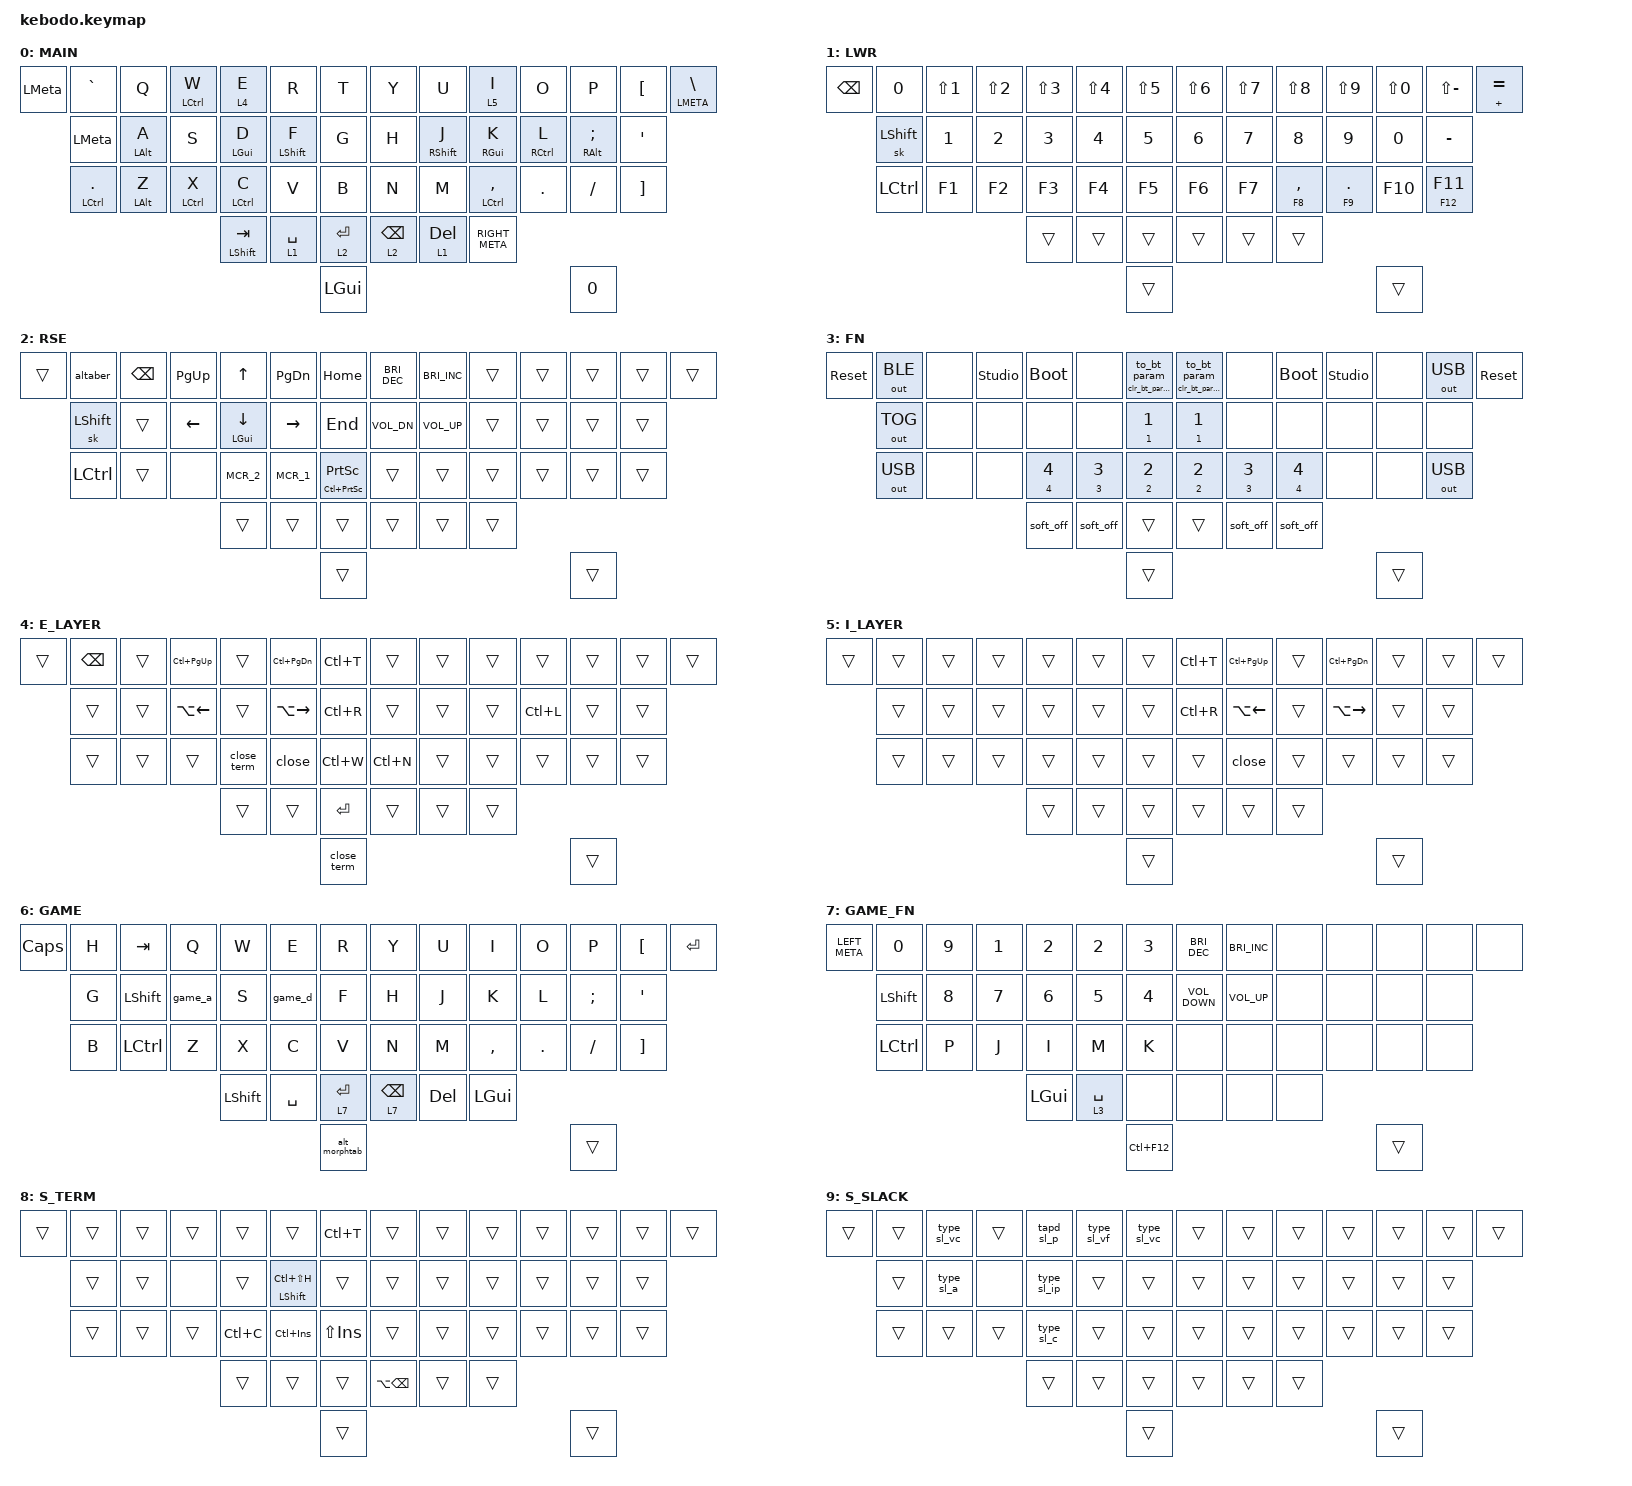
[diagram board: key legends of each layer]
/*
 * Copyright (c) 2020 The ZMK Contributors
 *
 * SPDX-License-Identifier: MIT
 */

#include <behaviors.dtsi>
#include <dt-bindings/zmk/bt.h>
#include <dt-bindings/zmk/keys.h>
#include <dt-bindings/zmk/outputs.h>

#define DEF 0
#define LWR 1
#define RSE 2
#define FN  3

&lt { require-prior-idle-ms = <140>; };

&mt {
    quick-tap-ms = <200>;
    flavor = "balanced";
};

/ {
    combos {
        compatible = "zmk,combos";

        game_mod_on {
            bindings = <&to 6>;
            key-positions = <6 5 39>;
            layers = <0 6>;
        };

        game_mod_off {
            bindings = <&to 0>;
            key-positions = <6 5 40>;
        };

        Esc {
            bindings = <&kp ESCAPE>;
            key-positions = <1 2>;
            layers = <0 1 6 7 3>;
        };

        slash {
            bindings = <&kp RA(SLASH)>;
            key-positions = <6 19>;
        };

        CapsWord {
            bindings = <&caps_word>;
            key-positions = <18 21>;
        };

        Backspace {
            bindings = <&kp INS>;
            key-positions = <11 12>;
        };

        at {
            bindings = <&kp AT_SIGN>;
            key-positions = <2 3>;
        };

        minus {
            bindings = <&tp_minus_underscore>;
            key-positions = <8 9>;
        };

        LPare {
            bindings = <&kp LEFT_PARENTHESIS>;
            key-positions = <21 22>;
        };

        RPare {
            bindings = <&kp RIGHT_PARENTHESIS>;
            key-positions = <22 23>;
        };

        Plus {
            bindings = <&tp_plus_equal>;
            key-positions = <9 10>;
        };

        Comma {
            bindings = <&kp RA(COMMA)>;
            key-positions = <33 32>;
        };

        Question {
            bindings = <&kp RA(QUESTION)>;
            key-positions = <7 8>;
        };

        Dot {
            bindings = <&kp RA(PERIOD)>;
            key-positions = <20 21>;
        };

        LBrac {
            bindings = <&mt LEFT_BRACE LEFT_BRACKET>;
            key-positions = <33 34>;
        };

        RBrac {
            bindings = <&mt RIGHT_BRACE RIGHT_BRACKET>;
            key-positions = <34 35>;
        };

        Quotes {
            bindings = <&kp RA(SQT)>;
            key-positions = <24 23>;
        };

        ret {
            bindings = <&kp RET>;
            key-positions = <22 23 21>;
        };

        bspace2 {
            bindings = <&morph_del>;
            key-positions = <17 16>;
            layers = <0 1 2>;
        };

        Question2 {
            bindings = <&kp RA(QUESTION)>;
            key-positions = <11 10>;
            layers = <0 1 2 3 4>;
        };

        toSwap {
            bindings = <&kp LC(LA(LS(C)))>;
            key-positions = <28 29>;
            layers = <0>;
        };

        at2 {
            bindings = <&kp AT_SIGN>;
            key-positions = <3 4>;
        };

        esc2 {
            bindings = <&kp ESCAPE>;
            key-positions = <2 3>;
            layers = <6 7>;
        };
    };

    behaviors {
        altaber: altaber {
            compatible = "zmk,behavior-tri-state";
            label = "ALT Win Switcher";
            #binding-cells = <0>;
            bindings = <&kt LGUI>, <&kp TAB>, <&kt LGUI>;
        };

        bt_select: bt_select {
            compatible = "zmk,behavior-hold-tap";
            label = "BT_SELECT";
            bindings = <&clr_bt_param>, <&to_bt_param>;

            #binding-cells = <2>;
            tapping-term-ms = <3000>;
        };

        LMeta: LMeta {
            compatible = "zmk,behavior-mod-morph";
            label = "LMETA";
            bindings = <&mt LEFT_META LG(SPACE)>, <&altaber>;

            #binding-cells = <0>;
            mods = <(MOD_LSFT)>;
        };

        alt_morphtab: alt_morphtab {
            compatible = "zmk,behavior-mod-morph";
            label = "ALT_MORPHTAB";
            bindings = <&kp LEFT_ALT>, <&kp TAB>;

            #binding-cells = <0>;
            mods = <(MOD_LALT|MOD_RALT|MOD_RGUI|MOD_LGUI)>;
            keep-mods = <(MOD_LALT|MOD_RALT|MOD_LGUI|MOD_RGUI)>;
        };

        morph_del: morph_del {
            compatible = "zmk,behavior-mod-morph";
            label = "MORPH_DEL";
            bindings = <&kp BACKSPACE>, <&kp DEL>;

            #binding-cells = <0>;
            mods = <(MOD_LSFT)>;
        };

        HR: HR {
            compatible = "zmk,behavior-hold-tap";
            label = "HR";
            bindings = <&kp>, <&kp>;

            #binding-cells = <2>;
            tapping-term-ms = <180>;
            flavor = "balanced";
            require-prior-idle-ms = <140>;
            quick-tap-ms = <(-1)>;
        };

        HR_S: HR_S {
            compatible = "zmk,behavior-hold-tap";
            label = "HR_S";
            bindings = <&kp>, <&kp>;

            #binding-cells = <2>;
            tapping-term-ms = <180>;
            flavor = "balanced";
            require-prior-idle-ms = <140>;
            hold-while-undecided;
            quick-tap-ms = <(-1)>;
        };

        HR_C: HR_C {
            compatible = "zmk,behavior-hold-tap";
            label = "HR_C";
            bindings = <&kp>, <&kp>;

            #binding-cells = <2>;
            tapping-term-ms = <180>;
            flavor = "tap-preferred";
            require-prior-idle-ms = <140>;
            hold-while-undecided;
            quick-tap-ms = <(-1)>;
        };

        tp_plus_equal: tp_plus_equal {
            compatible = "zmk,behavior-mod-morph";
            label = "TP_PLUS_EQUAL";
            bindings = <&kp KP_EQUAL>, <&kp PLUS>;

            #binding-cells = <0>;
            mods = <(MOD_LSFT|MOD_RSFT)>;
        };

        tp_minus_underscore: tp_minus_underscore {
            compatible = "zmk,behavior-mod-morph";
            label = "TP_MINUS_UNDERSCORE";
            bindings = <&kp MINUS>, <&kp UNDERSCORE>;

            #binding-cells = <0>;
            mods = <(MOD_LSFT|MOD_RSFT)>;
        };

        HR_A: HR_A {
            compatible = "zmk,behavior-hold-tap";
            label = "HR_A";
            bindings = <&kp>, <&kp>;

            #binding-cells = <2>;
            tapping-term-ms = <180>;
            flavor = "tap-preferred";
            require-prior-idle-ms = <140>;
            quick-tap-ms = <(-1)>;
        };

        thumb_lt: thumb_lt {
            compatible = "zmk,behavior-hold-tap";
            label = "THUMB_LT";
            bindings = <&mo>, <&kp>;

            #binding-cells = <2>;
            tapping-term-ms = <180>;
            quick-tap-ms = <220>;
            require-prior-idle-ms = <140>;
            flavor = "tap-preferred";
        };

        tapd_sl_p: tapd_sl_p {
            compatible = "zmk,behavior-tap-dance";
            label = "TAPD_SL_P";
            #binding-cells = <0>;
            tapping-term-ms = <2000>;
            bindings = <&type_sl_p>, <&type_sl_priority>;
        };
    };

    macros {
        to_bt_param: to_bt_param {
            compatible = "zmk,behavior-macro-one-param";
            #binding-cells = <1>;
            bindings =
                <&macro_press>,
                <&out OUT_BLE &macro_param_1to2>,
                <&macro_press>,
                <&bt BT_SEL MACRO_PLACEHOLDER>;

            label = "TO_BT_PARAM";
        };

        clr_bt_param: clr_bt_param {
            compatible = "zmk,behavior-macro-one-param";
            #binding-cells = <1>;
            bindings =
                <&macro_press>,
                <&out OUT_BLE &macro_param_1to2>,
                <&macro_press>,
                <&bt BT_SEL MACRO_PLACEHOLDER>,
                <&macro_press>,
                <&bt BT_CLR>;

            label = "CLR_BT_PARAM";
        };

        close_term: close_term {
            compatible = "zmk,behavior-macro";
            #binding-cells = <0>;
            bindings = <&kp Q &kp LC(C) &kp LC(D)>;
            label = "CLOSE_TERM";
        };

        game_d: game_d {
            compatible = "zmk,behavior-macro";
            #binding-cells = <0>;
            bindings =
                <&macro_release>,
                <&kp A>,
                <&macro_press>,
                <&kp D>,
                <&macro_pause_for_release>,
                <&macro_release>,
                <&kp D>;

            label = "GAME_D";
        };

        game_a: game_a {
            compatible = "zmk,behavior-macro";
            #binding-cells = <0>;
            bindings =
                <&macro_release>,
                <&kp D>,
                <&macro_press>,
                <&kp A>,
                <&macro_pause_for_release>,
                <&macro_release>,
                <&kp A>;

            label = "GAME_A";
        };

        MCR_1: MCR_1 {
            compatible = "zmk,behavior-macro";
            #binding-cells = <0>;
            bindings = <&kp LS(LC(F1)) &kp LS(C) &kp O &kp D &kp E &kp N1 &kp LS(W) &kp E &kp W &kp E>;
            label = "MCR_1";
        };

        MCR_2: MCR_2 {
            compatible = "zmk,behavior-macro";
            #binding-cells = <0>;
            bindings = <&kp LC(LS(F1)) &kp D &kp I &kp N9 &kp B &kp S &kp LS(D) &kp U &kp N>;
            label = "MCR_2";
        };

        close: close {
            compatible = "zmk,behavior-macro";
            #binding-cells = <0>;
            bindings = <&kp LC(W) &kp F13>;
            label = "CLOSE";
        };

        type_sl_a: type_sl_a {
            compatible = "zmk,behavior-macro";
            #binding-cells = <0>;
            bindings = <&kp LS(LC(F1)) &kp PERIOD &kp DOT &kp A>;
            label = "TYPE_SL_A";
        };

        type_sl_ip: type_sl_ip {
            compatible = "zmk,behavior-macro";
            #binding-cells = <0>;
            bindings = <&kp LS(LC(F1)) &kp DOT &kp DOT &kp I &kp P &kp SPACE>;
            label = "TYPE_SL_IP";
        };

        type_sl_vf: type_sl_vf {
            compatible = "zmk,behavior-macro";
            #binding-cells = <0>;
            bindings = <&kp LS(LC(F1)) &kp DOT &kp DOT &kp V &kp F &kp SPACE>;
            label = "TYPE_SL_VF";
        };

        type_sl_vc: type_sl_vc {
            compatible = "zmk,behavior-macro";
            #binding-cells = <0>;
            bindings = <&kp LS(LC(F1)) &kp DOT &kp DOT &kp V &kp C &kp SPACE &kp D &kp O &kp N &kp E>;
            label = "TYPE_SL_VC";
        };

        type_sl_c: type_sl_c {
            compatible = "zmk,behavior-macro";
            #binding-cells = <0>;
            bindings = <&kp RS(LS(F1)) &kp DOT &kp DOT &kp C &kp SPACE>;
            label = "TYPE_SL_C";
        };

        type_systemctl: type_systemctl {
            compatible = "zmk,behavior-macro";
            #binding-cells = <0>;
            bindings = <&kp LS(LC(F1)) &kp S &kp Y &kp S &kp T &kp E &kp M &kp C &kp T &kp L &kp SPACE>;
            label = "TYPE_SYSTEMCTL";
        };

        type_user: type_user {
            compatible = "zmk,behavior-macro";
            #binding-cells = <0>;
            bindings = <&kp RS(LS(F1)) &kp MINUS &kp MINUS &kp U &kp S &kp E &kp R &kp SPACE>;
            label = "TYPE_USER";
        };

        type_status: type_status {
            compatible = "zmk,behavior-macro";
            #binding-cells = <0>;
            bindings = <&kp RS(LS(F1)) &kp S &kp T &kp A &kp T &kp U &kp S &kp SPACE>;
            label = "TYPE_STATUS";
        };

        type_sl_p: type_sl_p {
            compatible = "zmk,behavior-macro";
            #binding-cells = <0>;
            bindings = <&kp RS(LS(F1)) &kp DOT &kp DOT &kp P>;
            label = "TYPE_SL_P";
        };

        type_sl_priority: type_sl_priority {
            compatible = "zmk,behavior-macro";
            #binding-cells = <0>;
            bindings = <&kp R &kp I &kp O &kp R &kp I &kp T &kp Y &kp SPACE &kp LS(P) &kp N1>;
            label = "TYPE_SL_PRIORITY";
        };
    };

    keymap {
        compatible = "zmk,keymap";

        main {
            /* 
         ╭───────────────────────────────────╮                ╭───────────────────────────────────╮        
  ╭──────╯  ~  |  Q  |  W󰘴 |  E  |  R  |  T  │                │  Y  |  U  |  I  |  O  |  P  |  [  ╰───────╮
  │          |  A󰘵 |  S  |  D󰘳 |  F󰘶 |  G  │                │  H  |  J󰘶 |  K󰘳 |  L󰘴 |  ;󰘵 |  '     󰘳 \  │
  ╰──────╮  󰘵  |  Z  |  X  |  C  |  V  |  B  ╰─────╮    ╭─────╯  N  |  M  |  ,  |  .  |  /  |  ]  ╭───────╯
         ╰─────────────────╮ GUI |  󰌒  | 󱁐  | 󰌑  │    │ 󰁮  | 󰹾  |    ╭───────────────────────╯
                           ╰───────────────────────╯    ╰─────────────────╯
*/

            bindings = <
&LMeta  &kp GRAVE      &kp Q             &HR_C LCTRL W  &lt 4 E             &kp R              &kp T              &kp Y                  &kp U               &lt 5 I            &kp O          &kp P                      &kp LBKT           &mt LMETA BACKSLASH
        &LMeta         &HR_A LEFT_ALT A  &kp S          &HR LGUI D          &HR_S LSHFT F      &kp G              &kp H                  &HR_S RSHFT J       &HR RGUI K         &HR_C RCTRL L  &HR_A RIGHT_ALT SEMICOLON  &kp SQT
        &mt LCTRL DOT  &HR_A LEFT_ALT Z  &HR_C LCTRL X  &HR_C LCTRL C       &kp V              &kp B              &kp N                  &kp M               &HR_C LCTRL COMMA  &kp DOT        &kp FSLH                   &kp RIGHT_BRACKET
                                                        &mt LEFT_SHIFT TAB  &thumb_lt 1 SPACE  &thumb_lt 2 RET    &thumb_lt 2 BACKSPACE  &thumb_lt 1 DELETE  &kp RIGHT_META
                                                                                               &kp LGUI                                                                                        &kp N0
            >;

            label = "MAIN";
        };

        lwr {
            /* 
         ╭───────────────────────────────────╮                ╭────────────────────────────────────╮        
  ╭──────╯  󰁮  |  1  |  2  |  3  |  4  |  5  │                │  6  |  7  |  8  |  9  |  0  |  -   ╰───────╮
  │  󰁮     CTR |  !  |  @  |  #  |  $  |  %  │                │  ^  |  &  |  *  |  (  |  )  |  _       +=  │
  ╰──────╮ ALT |  󱊫  |  󱊬  |  󱊭  |  󱊮  |  󱊯  ╰─────╮    ╭─────╯  󱊰  |  󱊱  |  󱊲  |  󱊳  |  󱊴  | 󱊵 󱊶  ╭───────╯
         ╰─────────────────╮     |     |  󱎘  |     │    │     |  󱎘  |     ╭────────────────────────╯
                           ╰───────────────────────╯    ╰─────────────────╯
*/

            bindings = <
&kp BACKSPACE  &kp N0     &kp LS(N1)  &kp LS(N2)  &kp LS(N3)  &kp LS(N4)  &kp LS(N5)    &kp LS(N6)  &kp LS(N7)  &kp LS(N8)    &kp LS(N9)  &kp LS(N0)  &kp LS(MINUS)  &mt PLUS EQUAL
               &sk LSHFT  &kp N1      &kp N2      &kp N3      &kp N4      &kp N5        &kp N6      &kp N7      &kp N8        &kp N9      &kp N0      &kp MINUS
               &kp LCTRL  &kp F1      &kp F2      &kp F3      &kp F4      &kp F5        &kp F6      &kp F7      &mt F8 COMMA  &mt F9 DOT  &kp F10     &mt F12 F11
                                                  &trans      &trans      &trans        &trans      &trans      &trans
                                                                          &trans                                                          &trans
            >;

            label = "LWR";
        };

        rse {
            /* 
         ╭───────────────────────────────────╮                ╭───────────────────────────────────╮        
  ╭──────╯    |  󰁮  | PG |    | PG |  󰈙 │                │  󰃞  |  󰃠  |     |     |     |     ╰───────╮
  │         󰘶  |     |    |    |    |  󰈙 │                │    |    |     |     |     |             │
  ╰──────╮  󰘴  |     |     | mcr | mcr |  󰹑  ╰─────╮    ╭─────╯     |     |     |     |     |     ╭───────╯
         ╰─────────────────╮     |     |     |  󱎘  │    │  󱎘  |     |     ╭───────────────────────╯
                           ╰───────────────────────╯    ╰─────────────────╯
*/

            bindings = <
&trans  &altaber    &kp BACKSPACE  &kp PG_UP  &kp UP_ARROW             &kp PG_DN  &kp HOME                           &kp C_BRIGHTNESS_DEC  &kp C_BRIGHTNESS_INC  &trans  &trans  &trans  &trans  &trans
        &sk LSHIFT  &trans         &kp LEFT   &mt LEFT_GUI DOWN_ARROW  &kp RIGHT  &kp END                            &kp C_VOL_DN          &kp C_VOL_UP          &trans  &trans  &trans  &trans
        &kp LCTRL   &trans         &none      &MCR_2                   &MCR_1     &mt LC(PRINTSCREEN) PRINTSCREEN    &trans                &trans                &trans  &trans  &trans  &trans
                                              &trans                   &trans     &trans                             &trans                &trans                &trans
                                                                                  &trans                                                                                         &trans
            >;

            label = "RSE";
        };

        fn {
            /* 
         ╭───────────────────────────────────╮                ╭───────────────────────────────────╮        
  ╭──────╯  󰕓  |     |     |    |     |  0 │                │  0 |     |    |     |     |  󰕓  ╰───────╮
  │  󰑓     󰕓  |     |     |     |     |  1 │                │  1 |     |     |     |     |  󰕓     󰑓   │
  ╰──────╮    |     |     |  4 |  3 |  2 ╰─────╮    ╭─────╯  2 |  3 |  4 |     |     |    ╭───────╯
         ╰─────────────────╮    |    |  󱎘  |  󱎘  │    │  󱎘  |  󱎘  |    ╭───────────────────────╯
                           ╰───────────────────────╯    ╰─────────────────╯
*/

            bindings = <
&sys_reset  &out OUT_BLE  &none  &studio_unlock  &bootloader     &none           &bt_select 0 0    &bt_select 0 0  &none           &bootloader     &studio_unlock  &none   &out OUT_USB  &sys_reset
            &out OUT_TOG  &none  &none           &none           &none           &bt_select 1 1    &bt_select 1 1  &none           &none           &none           &none   &none
            &out OUT_USB  &none  &none           &bt_select 4 4  &bt_select 3 3  &bt_select 2 2    &bt_select 2 2  &bt_select 3 3  &bt_select 4 4  &none           &none   &out OUT_USB
                                                 &soft_off       &soft_off       &trans            &trans          &soft_off       &soft_off
                                                                                 &trans                                                                            &trans
            >;

            label = "FN";
        };

        e_layer {
            bindings = <
&trans  &kp BACKSPACE  &trans  &kp LC(PG_UP)       &trans       &kp LC(PG_DN)  &kp LC(T)      &trans     &trans  &trans  &trans     &trans  &trans  &trans
        &trans         &trans  &kp LA(LEFT_ARROW)  &trans       &kp LA(RIGHT)  &kp LC(R)      &trans     &trans  &trans  &kp LC(L)  &trans  &trans
        &trans         &trans  &trans              &close_term  &close         &kp LC(W)      &kp LC(N)  &trans  &trans  &trans     &trans  &trans
                                                   &trans       &trans         &kp RET        &trans     &trans  &trans
                                                                               &close_term                                          &trans
            >;

            label = "E_LAYER";
        };

        i_layer {
            bindings = <
&trans  &trans  &trans  &trans  &trans  &trans  &trans    &kp LC(T)  &kp LC(PG_UP)  &trans  &kp LC(PG_DN)  &trans  &trans  &trans
        &trans  &trans  &trans  &trans  &trans  &trans    &kp LC(R)  &kp LA(LEFT)   &trans  &kp LA(RIGHT)  &trans  &trans
        &trans  &trans  &trans  &trans  &trans  &trans    &trans     &close         &trans  &trans         &trans  &trans
                                &trans  &trans  &trans    &trans     &trans         &trans
                                                &trans                                                     &trans
            >;

            label = "I_LAYER";
        };

        game {
            /* 
         ╭───────────────────────────────────╮                ╭───────────────────────────────────╮        
  ╭──────╯  T  |  󰌒  |  Q  |  W  |  E  |  R  │                │     |     |     |     |     |     ╰───────╮
  │  󰘳      G  |  󰘶  |  S  |  D  |  D  |  F  │                │     |     |     |     |     |             │
  ╰──────╮  B  |  󰘴  |  X  |  X  |  C  |  V  ╰─────╮    ╭─────╯     |     |     |     |     |     ╭───────╯
         ╰─────────────────╮  󰘵  |  󰘶  |  󱁐  |  󰌑  │    │     |     |     ╭───────────────────────╯
                           ╰───────────────────────╯    ╰─────────────────╯
*/

            bindings = <
&kp CAPS  &kp H  &kp TAB    &kp Q    &kp W           &kp E      &kp R                &kp Y            &kp U       &kp I      &kp O    &kp P     &kp LBKT  &kp RET
          &kp G  &kp LSHFT  &game_a  &kp S           &game_d    &kp F                &kp H            &kp J       &kp K      &kp L    &kp SEMI  &kp SQT
          &kp B  &kp LCTRL  &kp Z    &kp X           &kp C      &kp V                &kp N            &kp M       &kp COMMA  &kp DOT  &kp FSLH  &kp RBKT
                                     &kp LEFT_SHIFT  &kp SPACE  &thumb_lt 7 ENTER    &lt 7 BACKSPACE  &kp DELETE  &kp LGUI
                                                                &alt_morphtab                                                         &trans
            >;

            label = "GAME";
        };

        game_fn {
            /* 
         ╭───────────────────────────────────╮                ╭───────────────────────────────────╮        
  ╭──────╯  󱊷  |  9  |  1  |  2  |  3  |  3  │                │     |     |     |     |     |     ╰───────╮
  │  󰁮      󰘶  |  8  |  7  |  6  |  5  |  4  │                │     |     |     |     |     |             │
  ╰──────╮  󰘴  |  P  |  J  |  I  |  M  |  K  ╰─────╮    ╭─────╯     |     |     |     |     |     ╭───────╯
         ╰─────────────────╮    |     |     |  󱎘  │    │  󱎘  |     |     ╭───────────────────────╯
                           ╰───────────────────────╯    ╰─────────────────╯
*/

            bindings = <
&kp LEFT_META  &kp N0          &kp N9  &kp N1  &kp N2        &kp N2             &kp N3         &kp C_BRIGHTNESS_DEC  &kp C_BRIGHTNESS_INC  &none  &none  &none   &none  &none
               &kp LEFT_SHIFT  &kp N8  &kp N7  &kp N6        &kp N5             &kp N4         &kp C_VOLUME_DOWN     &kp C_VOLUME_UP       &none  &none  &none   &none
               &kp LCTRL       &kp P   &kp J   &kp I         &kp M              &kp K          &none                 &none                 &none  &none  &none   &none
                                               &kp LEFT_GUI  &thumb_lt 3 SPACE  &none          &none                 &none                 &none
                                                                                &kp LC(F12)                                                              &trans
            >;

            label = "GAME_FN";
        };

        s_term {
            bindings = <
&trans  &trans  &trans  &trans  &trans     &trans                      &kp LC(T)      &trans             &trans  &trans  &trans  &trans  &trans  &trans
        &trans  &trans  &none   &trans     &HR_S LEFT_SHIFT LC(LS(H))  &trans         &trans             &trans  &trans  &trans  &trans  &trans
        &trans  &trans  &trans  &kp LC(C)  &kp LC(INS)                 &kp LS(INS)    &trans             &trans  &trans  &trans  &trans  &trans
                                &trans     &trans                      &trans         &kp LA(BACKSPACE)  &trans  &trans
                                                                       &trans                                                    &trans
            >;

            label = "S_TERM";
        };

        s_slack {
            bindings = <
&trans  &trans  &type_sl_vc  &trans  &tapd_sl_p   &type_sl_vf  &type_sl_vc    &trans  &trans  &trans  &trans  &trans  &trans  &trans
        &trans  &type_sl_a   &none   &type_sl_ip  &trans       &trans         &trans  &trans  &trans  &trans  &trans  &trans
        &trans  &trans       &trans  &type_sl_c   &trans       &trans         &trans  &trans  &trans  &trans  &trans  &trans
                                     &trans       &trans       &trans         &trans  &trans  &trans
                                                               &trans                                         &trans
            >;

            label = "S_SLACK";
        };
    };

    conditional_layers {
        compatible = "zmk,conditional-layers";

        Fn {
            if-layers = <1 2>;
            then-layer = <3>;
        };
    };
};

/* 
         ╭───────────────────────────────────╮                ╭───────────────────────────────────╮        
  ╭──────╯     |     |     |     |     |     │                │     |     |     |     |     |     ╰───────╮
  │            |     |     |     |     |     │                │     |     |     |     |     |             │
  ╰──────╮     |     |     |     |     |     ╰─────╮    ╭─────╯     |     |     |     |     |     ╭───────╯
         ╰─────────────────╮     |     |     |     │    │     |     |     ╭───────────────────────╯
                           ╰───────────────────────╯    ╰─────────────────╯
*/
